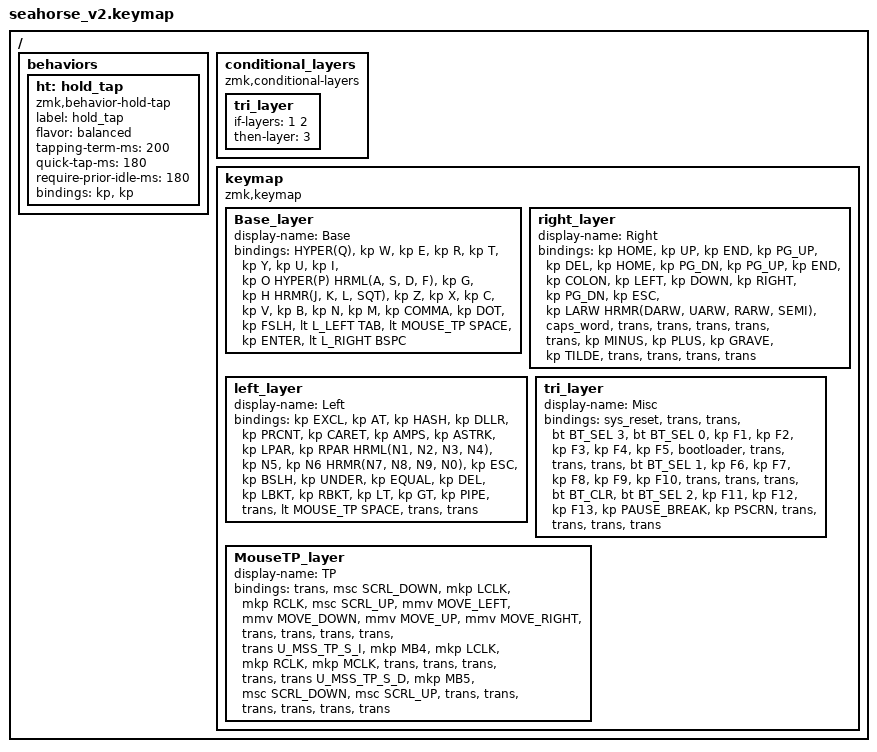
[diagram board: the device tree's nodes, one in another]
#include <behaviors.dtsi>
#include <dt-bindings/zmk/keys.h>
#include <dt-bindings/zmk/bt.h>

#define DEFAULT 0
#define L_RIGHT 1
#define L_LEFT 2
#define MOUSE_TP 4
#define MOUSE_KEYS 5 // TODO

/*
 * Defines to enable/disable features
 *
 * These defines allow us to conditionally enable and disable parts of the keymap config.
 *
 * For example, if we decide to build the firmware without the mouse features, we can
 * disable all the config options that rely on those forks and modules without having
 * to edit the entire keymap file manually every time.
 */
 
#define HAS_MOUSE_KEYS
#define HAS_MOUSE_TP

#ifdef HAS_MOUSE_KEYS
  #include <dt-bindings/zmk/pointing.h>
#endif

#ifdef HAS_MOUSE_TP
  #include "include/behavior_mouse_tp.dtsi"
#endif  
// TODO see if this is still needed
// #ifdef HAS_MOUSE_KEYS
//  #include "include/behavior_mouse_keys.dtsi"
// #endif

// Adjust layer keys based on enabled features.
//
// This prevents build errors when we build the firmware
// without the mouse keys PR or the TP module.
// TODO set conditional keys for mouse and trackpoint




// Home row mods macro
#define HRML(k1,k2,k3,k4) &ht LSHFT k1  &ht LALT k2  &ht LCTRL k3  &ht LGUI k4
#define HRMR(k1,k2,k3,k4) &ht RGUI k1  &ht RCTRL k2  &ht RALT k3  &ht RSHFT k4
#define HYPER(k1) &ht LS(LC(LA(LGUI))) k1

/ {
    behaviors {
        ht: hold_tap {
            label = "hold_tap";
            compatible = "zmk,behavior-hold-tap";
            #binding-cells = <2>;
            flavor = "balanced";
            tapping-term-ms = <200>;
            quick-tap-ms = <180>;
            require-prior-idle-ms = <180>;
            bindings = <&kp>, <&kp>;
        };
    };

    conditional_layers {
        compatible = "zmk,conditional-layers";
        tri_layer {
            if-layers = <1 2>;
            then-layer = <3>;
        };
    };

    keymap {
        compatible = "zmk,keymap";
        Base_layer {
            display-name = "Base";
            bindings = <
        //╭──────────┬──────────┬──────────┬──────────┬──────────╮   ╭──────────┬──────────┬──────────┬──────────┬──────────╮
        //│  Q       │  W       │  E       │  R       │  T       │   │  Y       │  U       │  I       │  O       │  P       │
            HYPER(Q)      &kp W      &kp E      &kp R      &kp T          &kp Y      &kp U      &kp I      &kp O   HYPER(P)
        //├──────────┼──────────┼──────────┼──────────┼──────────┤   ├──────────┼──────────┼──────────┼──────────┼──────────┤
        //│  A       │  S       │  D       │  F       │  G       │   │  H       │  J       │  K       │  L       │ ' "      │
            HRML(A,        S,         D,         F)     &kp G          &kp H      HRMR(J,        K,         L,        SQT)
        //├──────────┼──────────┼──────────┼──────────┼──────────┤   ├──────────┼──────────┼──────────┼──────────┼──────────┤
        //│  Z       │  X       │  C       │  V       │  B       │   │  N       │  M       │ , <      │ . >      │ / ?      │
            &kp Z      &kp X      &kp C      &kp V      &kp B          &kp N      &kp M      &kp COMMA  &kp DOT    &kp FSLH
        //╰──────────┴──────────┴──────────┼──────────┼──────────┤   ├──────────┼──────────┼──────────┴──────────┴──────────╯
                                &lt L_LEFT TAB  &lt MOUSE_TP SPACE    &kp ENTER  &lt L_RIGHT BSPC
        //                     ╰──────────────┴──────────────────╯   ╰──────────┴────────────────╯
            >;
        };

        right_layer {
            display-name = "Right";
            bindings = <
        //╭──────────┬──────────┬──────────┬──────────┬──────────╮   ╭──────────┬──────────┬──────────┬──────────┬──────────╮
        //│ HOME     │ UP       │  END     │ PAGE UP  │ DEL      │   │ HOME     │ PAGE DN  │ PAGE UP  │ END      │  :       │
            &kp HOME   &kp UP     &kp END   &kp PG_UP  &kp DEL          &kp HOME   &kp PG_DN  &kp PG_UP  &kp END    &kp COLON
        //├──────────┼──────────┼──────────┼──────────┼──────────┤   ├──────────┼──────────┼──────────┼──────────┼──────────┤
        //│ LEFT     │  DOWN    │ RIGHT    │ PAGE DOWN│ ESC      │   │ LEFT     │ DOWN     │ UP       │ RIGHT    │  ;       │
           &kp LEFT   &kp DOWN   &kp RIGHT  &kp PG_DN  &kp ESC         &kp LARW   HRMR(DARW,  UARW,    RARW,      SEMI)
        //├──────────┼──────────┼──────────┼──────────┼──────────┤   ├──────────┼──────────┼──────────┼──────────┼──────────┤
        //│ CAPS     │ PRINT SC │volume up │volume dwn│  Next    │   │ PREV SONG│    -     │     +    │   `      │   ~      │
           &caps_word  &trans   &trans      &trans     &trans         &trans      &kp MINUS  &kp PLUS   &kp GRAVE  &kp TILDE
        //╰──────────┴──────────┴──────────┼──────────┼──────────┤   ├──────────┼──────────┼──────────┴──────────┴──────────╯
                                             &trans      &trans        &trans     &trans
        //                                 ╰──────────┴──────────╯   ╰──────────┴──────────╯
            >;
        };

        left_layer {
            display-name = "Left";
            bindings = <
        //╭──────────┬──────────┬──────────┬──────────┬──────────╮   ╭──────────┬──────────┬──────────┬──────────┬──────────╮
        //│    !     │  @       │  #       │  $       │ %        │   │  ^       │  &       │  *       │  (       │  )       │
            &kp EXCL   &kp AT     &kp HASH   &kp DLLR   &kp PRCNT      &kp CARET   &kp AMPS   &kp ASTRK  &kp LPAR  &kp RPAR  
        //├──────────┼──────────┼──────────┼──────────┼──────────┤   ├──────────┼──────────┼──────────┼──────────┼──────────┤
        //│   1      │  2       │  3       │  4       │  5       │   │  6       │  7       │  8       │  9       │  0       │
            HRML(N1,    N2,       N3,        N4)        &kp N5         &kp N6     HRMR(N7,   N8,        N9,         N0)
        //├──────────┼──────────┼──────────┼──────────┼──────────┤   ├──────────┼──────────┼──────────┼──────────┼──────────┤
        //│  esc     │          │  _       │    =     │  del     │   │  [       │   ]      │  <       │  >       │         │
           &kp ESC     &kp BSLH  &kp UNDER &kp EQUAL   &kp DEL       &kp LBKT    &kp RBKT   &kp LT     &kp GT     &kp PIPE  
        //╰──────────┴──────────┴──────────┼──────────┼──────────┤   ├──────────┼──────────┼──────────┴──────────┴──────────╯
                                             &trans &lt MOUSE_TP SPACE      &trans     &trans
        //                                 ╰──────────┴──────────╯   ╰──────────┴──────────╯
            >;
        };

        tri_layer {
            display-name = "Misc";
            bindings = <
        //╭──────────┬──────────┬──────────┬──────────┬──────────╮   ╭──────────┬──────────┬──────────┬──────────┬──────────╮
        //│ RESET    │          │          │ PROFILE  │PROFILE 0 │   │   F1     │   F2     │   F3     │   F4     │   F5     │
            &sys_reset  &trans     &trans  &bt BT_SEL 3 &bt BT_SEL 0   &kp F1    &kp F2     &kp F3     &kp F4    &kp F5
        //├──────────┼──────────┼──────────┼──────────┼──────────┤   ├──────────┼──────────┼──────────┼──────────┼──────────┤
        //│BOOTLOADER│          │          │          │PROFILE 1 │   │   F6     │   F7     │   F8     │   F9     │   F10    │
          &bootloader  &trans     &trans     &trans    &bt BT_SEL 1    &kp F6    &kp F7     &kp F8     &kp F9    &kp F10
        //├──────────┼──────────┼──────────┼──────────┼──────────┤   ├──────────┼──────────┼──────────┼──────────┼──────────┤
        //│          │          │          │ CLEAR BT │PROFILE 2 │   │   F11    │   F12    │   F13       │   PAUSE  │  PRINT   │
            &trans     &trans     &trans    &bt BT_CLR &bt BT_SEL 2    &kp F11   &kp F12    &kp F13  &kp PAUSE_BREAK &kp PSCRN
        //╰──────────┴──────────┴──────────┼──────────┼──────────┤   ├──────────┼──────────┼──────────┴──────────┴──────────╯
                                             &trans     &trans         &trans     &trans
        //                                 ╰──────────┴──────────╯   ╰──────────┴──────────╯
            >;
        };

        MouseTP_layer {
            display-name = "TP";
            bindings = <
        //╭─────────────┬─────────────┬─────────────┬─────────────┬─────────────╮   ╭─────────────┬─────────────┬─────────────┬─────────────┬─────────────╮
        //│             │             │             │             │             │   │             │             │             │             │             │
            &trans        &msc SCRL_DOWN       &mkp LCLK    &mkp RCLK      &msc SCRL_UP        &mmv MOVE_LEFT &mmv MOVE_DOWN &mmv MOVE_UP &mmv MOVE_RIGHT  &trans
        //├─────────────┼─────────────┼─────────────┼─────────────┼─────────────┤   ├─────────────┼─────────────┼─────────────┼─────────────┼─────────────┤
        //│             │             │             │             │             │   │   MB4       │  LFT_CLK    │ RGHT_CLK    │ MDL_CLK     │             │
            &trans        &trans        &trans        &trans        U_MSS_TP_S_I       &mkp MB4     &mkp LCLK     &mkp RCLK     &mkp MCLK      &trans
        //├─────────────┼─────────────┼─────────────┼─────────────┼─────────────┤   ├─────────────┼─────────────┼─────────────┼─────────────┼─────────────┤
        //│             │             │             │             │             │   │     MB5     │    SCR_DWN   │    SCR_UP  │             │             │
             &trans        &trans      &trans         &trans      U_MSS_TP_S_D        &mkp MB5     &msc SCRL_DOWN &msc SCRL_UP   &trans       &trans
        //╰─────────────┴─────────────┴─────────────┼─────────────┼─────────────┤   ├─────────────┼─────────────┼─────────────┴─────────────┴─────────────╯
                                                          &trans     &trans              &trans     &trans
        //                                          ╰─────────────┴─────────────╯   ╰─────────────┴─────────────╯
            >;
        };

    };
};
